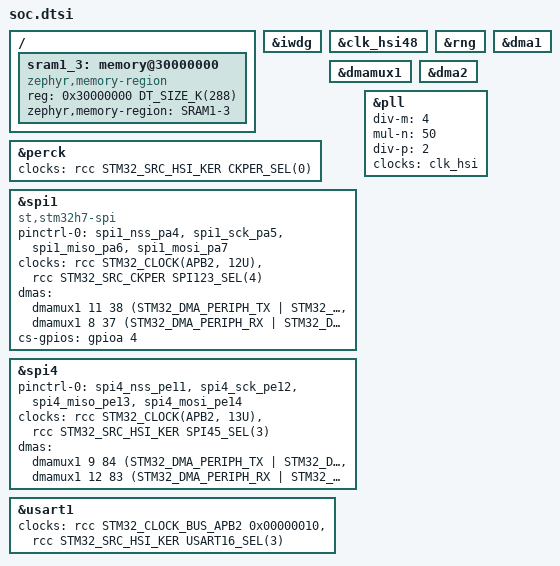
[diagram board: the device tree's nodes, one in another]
/* Copyright 2024 The ChromiumOS Authors.
 * Use of this source code is governed by a BSD-style license that can be
 * found in the LICENSE file.
 */

#include <cros/st/stm32.dtsi>
#include <zephyr/dt-bindings/pinctrl/stm32-pinctrl.h>
#include <st/h7/stm32h743vitx-pinctrl.dtsi>

&iwdg {
	status = "okay";
};

//&timers9 {
//	/*
//	 * The counter has 16 bits. TIMPRE bit in RCC_DCKCFGR is 0 by default.
//	 * On Dragonclaw board APB2 prescaler is set to 2. In this case APB2
//	 * clock is 48Mhz, but TIM9 input clock is doubled, because TIMPRE=0
//	 * and APB2 prescaler > 1. Effectively TIM9 is clocked with 96Mhz clock.
//	 * Setting prescaler to 16384 will give about 11.2s maximum timeout.
//	 */
//	st,prescaler = <0x4000>;
//	status = "okay";
//	wdg_helper_counter: counter {
//		status = "okay";
//	};
//};
//
//&wdg_helper {
//	counter = <&wdg_helper_counter>;
//	status = "okay";
//};

/* RNG module uses hsi48 clock as a source by default. */
/* TODO: Enable only to get random number. Connect it to RNG and device suspend and resume?. */
&clk_hsi48 {
	status = "okay";
};

&perck {
	status = "okay";
	clocks = <&rcc STM32_SRC_HSI_KER CKPER_SEL(0)>;
};

&rng {
	status = "okay";
};

&dmamux1 {
	status = "okay";
};

// TODO USE only DMA2?
&dma1 {
	status = "okay";
};

&dma2 {
	status = "okay";
};

&spi1 {
	compatible = "st,stm32h7-spi", "st,stm32-spi-host-cmd", "st,stm32-spi-fifo";
	status = "okay";

	pinctrl-0 = <&spi1_nss_pa4 &spi1_sck_pa5 &spi1_miso_pa6 &spi1_mosi_pa7>;
	pinctrl-names = "default";

	/* Select per_ck(hsi_ker_ck) as source clock for SPI1 */
	clocks = <&rcc STM32_CLOCK(APB2, 12U)>,
		 <&rcc STM32_SRC_CKPER SPI123_SEL(4)>;

	dmas = <&dmamux1 11 38 (STM32_DMA_PERIPH_TX | STM32_DMA_PRIORITY_VERY_HIGH)
		 &dmamux1 8 37 (STM32_DMA_PERIPH_RX | STM32_DMA_PRIORITY_VERY_HIGH)>;
	dma-names = "tx", "rx";

	/* This field is used to point at our CS pin */
	cs-gpios = <&gpioa 4 (GPIO_PULL_UP)>;
};

&spi4 {
//	pinctrl-0 = <&spi4_nss_pe4 &spi4_sck_pe2
//		     &spi4_miso_pe5 &spi4_mosi_pe6>;
//	dev config
	pinctrl-0 = <&spi4_nss_pe11 &spi4_sck_pe12
		     &spi4_miso_pe13 &spi4_mosi_pe14>;
	pinctrl-names = "default";

	/* Select hsi_ker_ck as source clock for SPI4 */
	clocks = <&rcc STM32_CLOCK(APB2, 13U)>,
		 <&rcc STM32_SRC_HSI_KER SPI45_SEL(3)>;

	//Channels for compability. TODO USE only one DMA?
	dmas = <&dmamux1 9 84 (STM32_DMA_PERIPH_TX | STM32_DMA_PRIORITY_HIGH)
		 &dmamux1 12 83 (STM32_DMA_PERIPH_RX | STM32_DMA_PRIORITY_HIGH)>;
	dma-names = "tx", "rx";
};

//&flash0 {
//	/*
//	 * 4 byte parallelism can be enabled when the voltage is at least 2.7V.
//	 * See STM32F412 reference manual for more details.
//	 */
//	write-block-size = <4>;
//};
//

/ {
	/* Overwrite SRAM1 node, to a common node handling SRAM1, SRAM2 and
	 * SRAM3. This is contious memory anyway. We need that to store
	 * big FP buffers.
	 */
	sram1_3: memory@30000000 {
		compatible = "zephyr,memory-region";
		reg = <0x30000000 DT_SIZE_K(288)>;
		zephyr,memory-region = "SRAM1-3";
	};

};
/* SRAM2 and SRAM3 memory is handled by a common sram1_3 node. */
/delete-node/ &sram2;
/delete-node/ &sram3;

/* Configure to use . */
&pll {
	div-m = <4>;
	mul-n = <50>;
	div-p = <2>;
	clocks = <&clk_hsi>;
	status = "okay";
};

//&rcc {
//	/* TODO check APB1-4 enr, if enabled - rather yes */
//	d1ppre = <2>;
//	d2ppre1 = <2>;
//	d2ppre2 = <2>;
//	d3ppre = <2>;
//};

&usart1 {
	/* Select hsi_ker_ck as source clock for USART1 */
	clocks = <&rcc STM32_CLOCK_BUS_APB2 0x00000010>,
		 <&rcc STM32_SRC_HSI_KER USART16_SEL(3)>;
};
